# WDT_A_356.0 register map
Vendor: Texas Instruments
Peripheral module from a debugger description file (folder msp430).
Registers are 16-bit, read-write, no defined reset value unless marked. A register's access mark holds for its fields unless they carry their own. Offsets are as the file gives them; lines under a group give offsets from that group; [hi:lo] are bit positions; {n}, {i} and the like mark numbered series; 'fields as' and 'values as' point back to an identical list; <NAME> marks a mode.

## WDT_A
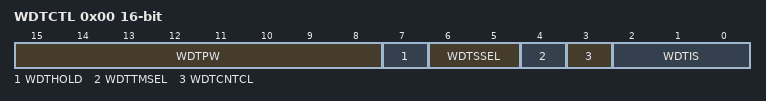
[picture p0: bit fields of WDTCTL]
0x00 WDTCTL — Watchdog Timer Control Register
  [15:8] WDTPW — Watchdog timer password
  [7] WDTHOLD — Watchdog timer hold
    0=UNHOLD (Watchdog timer is not stopped); 1=HOLD (Watchdog timer is stopped)
  [6:5] WDTSSEL — Watchdog timer clock source select
    0=SMCLK; 1=ACLK; 2=VLOCLK; 3=BCLK
  [4] WDTTMSEL — Watchdog timer mode select
    0=Watchdog mode; 1=Interval timer mode
  [3] WDTCNTCL — Watchdog timer counter clear
    0=No action; 1=WDTCNT = 0000h
  [2:0] WDTIS — Watchdog timer interval select
    0=2G (Watchdog clock source / (2^(31)) (18:12:16 at 32.768 kHz)); 1=128M (Watchdog clock source /(2^(27)) (01:08:16 at 32.768 kHz)); 2=8192K (Watchdog clock source /(2^(23)) (00:04:16 at 32.768 kHz)); 3=512K (Watchdog clock source /(2^(19)) (00:00:16 at 32.768 kHz)); 4=32K (Watchdog clock source /(2^(15)) (1 s at 32.768 kHz)); 5=Watchdog clock source / (2^(13)) (250 ms at 32.768 kHz); 6=Watchdog clock source / (2^(9)) (15.625 ms at 32.768 kHz); 7=Watchdog clock source / (2^(6)) (1.95 ms at 32.768 kHz)
